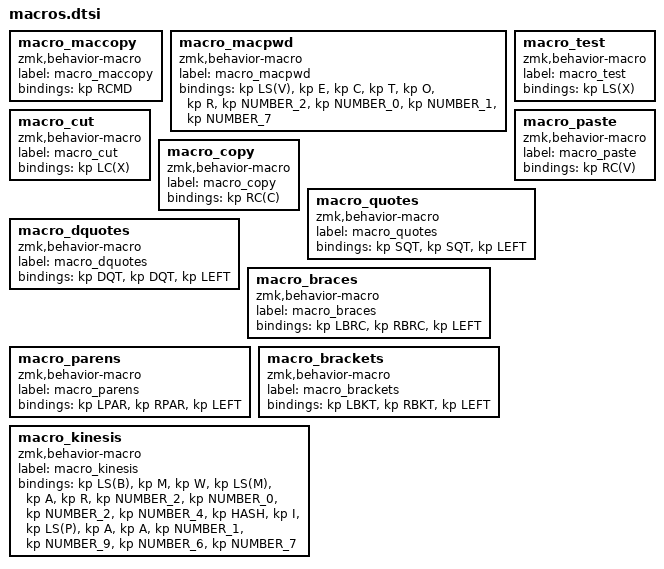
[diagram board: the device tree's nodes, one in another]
macro_maccopy: macro_maccopy{
compatible = "zmk,behavior-macro";
label = "macro_maccopy";
#binding-cells = <0>;
bindings = <&kp RCMD>;
};
macro_macpwd: macro_macpwd{
compatible = "zmk,behavior-macro";
label = "macro_macpwd";
#binding-cells = <0>;
bindings = <&kp LS(V)>, <&kp E>, <&kp C>, <&kp T>, <&kp O>, <&kp R>, <&kp NUMBER_2>, <&kp NUMBER_0>, <&kp NUMBER_1>, <&kp NUMBER_7>;
};
macro_test: macro_test{
compatible = "zmk,behavior-macro";
label = "macro_test";
#binding-cells = <0>;
bindings = <&kp LS(X)>;
};
macro_cut: macro_cut{
compatible = "zmk,behavior-macro";
label = "macro_cut";
#binding-cells = <0>;
bindings = <&kp LC(X)>;
};
macro_paste: macro_paste{
compatible = "zmk,behavior-macro";
label = "macro_paste";
#binding-cells = <0>;
bindings = <&kp RC(V)>;
};
macro_copy: macro_copy{
compatible = "zmk,behavior-macro";
label = "macro_copy";
#binding-cells = <0>;
bindings = <&kp RC(C)>;
};
macro_quotes: macro_quotes{
compatible = "zmk,behavior-macro";
label = "macro_quotes";
#binding-cells = <0>;
bindings = <&kp SQT>, <&kp SQT>, <&kp LEFT>;
};
macro_dquotes: macro_dquotes{
compatible = "zmk,behavior-macro";
label = "macro_dquotes";
#binding-cells = <0>;
bindings = <&kp DQT>, <&kp DQT>, <&kp LEFT>;
};
macro_braces: macro_braces{
compatible = "zmk,behavior-macro";
label = "macro_braces";
#binding-cells = <0>;
bindings = <&kp LBRC>, <&kp RBRC>, <&kp LEFT>;
};
macro_parens: macro_parens{
compatible = "zmk,behavior-macro";
label = "macro_parens";
#binding-cells = <0>;
bindings = <&kp LPAR>, <&kp RPAR>, <&kp LEFT>;
};
macro_brackets: macro_brackets{
compatible = "zmk,behavior-macro";
label = "macro_brackets";
#binding-cells = <0>;
bindings = <&kp LBKT>, <&kp RBKT>, <&kp LEFT>;
};
macro_kinesis: macro_kinesis{
compatible = "zmk,behavior-macro";
label = "macro_kinesis";
#binding-cells = <0>;
bindings = <&kp LS(B)>, <&kp M>, <&kp W>, <&kp LS(M)>, <&kp A>, <&kp R>, <&kp NUMBER_2>, <&kp NUMBER_0>, <&kp NUMBER_2>, <&kp NUMBER_4>, <&kp HASH>, <&kp I>, <&kp LS(P)>, <&kp A>, <&kp A>, <&kp NUMBER_1>, <&kp NUMBER_9>, <&kp NUMBER_6>, <&kp NUMBER_7>;
};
